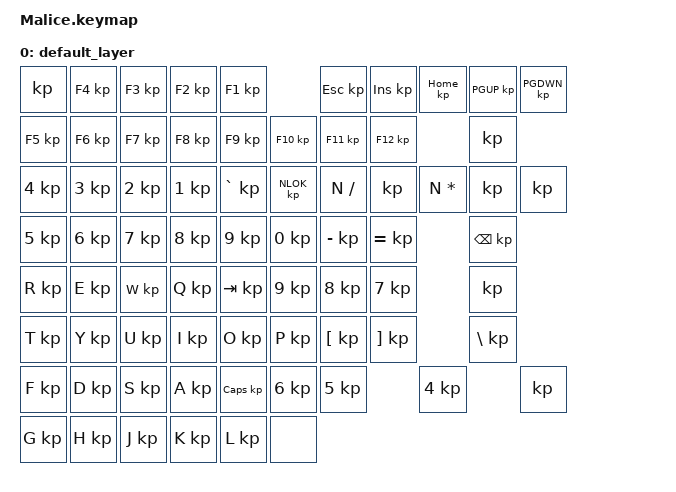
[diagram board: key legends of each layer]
#include <behaviors.dtsi>
#include <dt-bindings/zmk/keys.h>
#include <dt-bindings/zmk/bt.h>
#include <dt-bindings/zmk/rgb.h>
#include <dt-bindings/zmk/backlight.h>

/ {
    keymap {
        compatible = "zmk,keymap";

        default_layer { // Layer 0
            // -------------------------------------
            // |     Z     |     M     |     K     |
            // |     A     |     B     |     C     |
            // |     D     |     E     |     F     |
            bindings = <
                kp& F4	kp& F3	kp& F2	kp& F1	kp& ESC	kp& INS	kp& HOME	kp& PGUP	kp& PGDWN
                kp& F5	kp& F6	kp& F7	kp& F8	kp& F9	kp& F10	kp& F11	kp& F12	kp& 
                kp& 4	kp& 3	kp& 2	kp& 1	kp& `	kp& NLOK	kp& N/	kp& N*	kp& 
                kp& 5	kp& 6	kp& 7	kp& 8	kp& 9	kp& 0	kp& -	kp& =	kp& BKSP
                kp& R	kp& E	kp& W	kp& Q	kp& TAB	kp& N9	kp& N8	kp& N7	kp& 
                kp& T	kp& Y	kp& U	kp& I	kp& O	kp& P	kp& [	kp& ]	kp& \
                kp& F	kp& D	kp& S	kp& A	kp& CAPS	kp& N6	kp& N5	kp& N4	kp& 
                kp& G	kp& H	kp& J	kp& K	kp& L	kp& ;	kp& '	kp& ENTER	kp& DEL
                kp& V	kp& C	kp& X	kp& Z	kp& LSHIFT	kp& N3	kp& N2	kp& N1	kp& 
                kp& B	kp& N	kp& M	kp& ,	kp& .	kp& /	kp& RSHIFT	kp& UP	kp& END
                kp& 	kp& NUM+	kp& LALT	kp& LWIN	kp& LCTRL	kp& N0	kp& N.	kp& NENTER	kp& N-
                kp& SPACE	kp& RALT	kp& RWIN	kp& MENU	kp& RCTRL	kp& LEFT	kp& DOWN	kp& RIGHT	kp& 
            >;
        };
    };
 };

